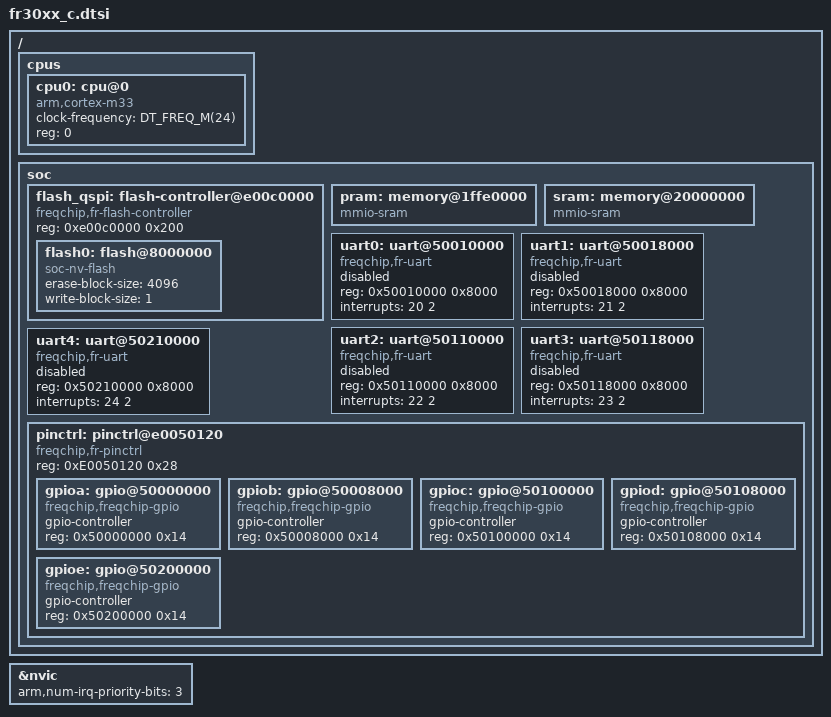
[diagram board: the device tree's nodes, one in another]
/*
 * Copyright (c) 2025 Freqchip
 *
 * SPDX-License-Identifier: Apache-2.0
 */

#include <freq.h>
#include <mem.h>
#include <arm/armv8-m.dtsi>
#include <zephyr/dt-bindings/gpio/gpio.h>

/ {
	cpus {
		#address-cells = <1>;
		#size-cells = <0>;

		cpu0: cpu@0 {
			compatible = "arm,cortex-m33";
			clock-frequency = <DT_FREQ_M(24)>;
			reg = <0>;
			#address-cells = <1>;
			#size-cells = <1>;
		};
	};

	soc {
        flash_qspi: flash-controller@e00c0000 {
			compatible = "freqchip,fr-flash-controller";
			reg = <0xe00c0000 0x200>;

			#address-cells = <1>;
			#size-cells = <1>;

			flash0: flash@8000000 {
				compatible = "soc-nv-flash";
				erase-block-size = <4096>;
				write-block-size = <1>;
			};
        };

		pram: memory@1ffe0000 {
			compatible = "mmio-sram";
		};

		sram: memory@20000000 {
			compatible = "mmio-sram";
		};

		uart0: uart@50010000 {
            compatible = "freqchip,fr-uart";
            reg = <0x50010000 0x8000>;
			interrupts = <20 2>;
			status = "disabled";
		};

		uart1: uart@50018000 {
            compatible = "freqchip,fr-uart";
            reg = <0x50018000 0x8000>;
			interrupts = <21 2>;
			status = "disabled";
		};

		uart2: uart@50110000 {
            compatible = "freqchip,fr-uart";
            reg = <0x50110000 0x8000>;
			interrupts = <22 2>;
			status = "disabled";
		};

		uart3: uart@50118000 {
            compatible = "freqchip,fr-uart";
            reg = <0x50118000 0x8000>;
			interrupts = <23 2>;
			status = "disabled";
		};

		uart4: uart@50210000 {
            compatible = "freqchip,fr-uart";
            reg = <0x50210000 0x8000>;
			interrupts = <24 2>;
			status = "disabled";
		};

		pinctrl: pinctrl@e0050120 {
			compatible = "freqchip,fr-pinctrl";
			#address-cells = <1>;
			#size-cells = <1>;
			reg = <0xE0050120 0x28>;

			gpioa: gpio@50000000 {
				compatible = "freqchip,freqchip-gpio";
				gpio-controller;
				#gpio-cells = <2>;
				reg = <0x50000000 0x14>;
			};
			gpiob: gpio@50008000 {
				compatible = "freqchip,freqchip-gpio";
				gpio-controller;
				#gpio-cells = <2>;
				reg = <0x50008000 0x14>;
			};
			gpioc: gpio@50100000 {
				compatible = "freqchip,freqchip-gpio";
				gpio-controller;
				#gpio-cells = <2>;
				reg = <0x50100000 0x14>;
			};
			gpiod: gpio@50108000 {
				compatible = "freqchip,freqchip-gpio";
				gpio-controller;
				#gpio-cells = <2>;
				reg = <0x50108000 0x14>;
			};
			gpioe: gpio@50200000 {
				compatible = "freqchip,freqchip-gpio";
				gpio-controller;
				#gpio-cells = <2>;
				reg = <0x50200000 0x14>;
			};
		};
	};
};

&nvic {
	arm,num-irq-priority-bits = <3>;
};
